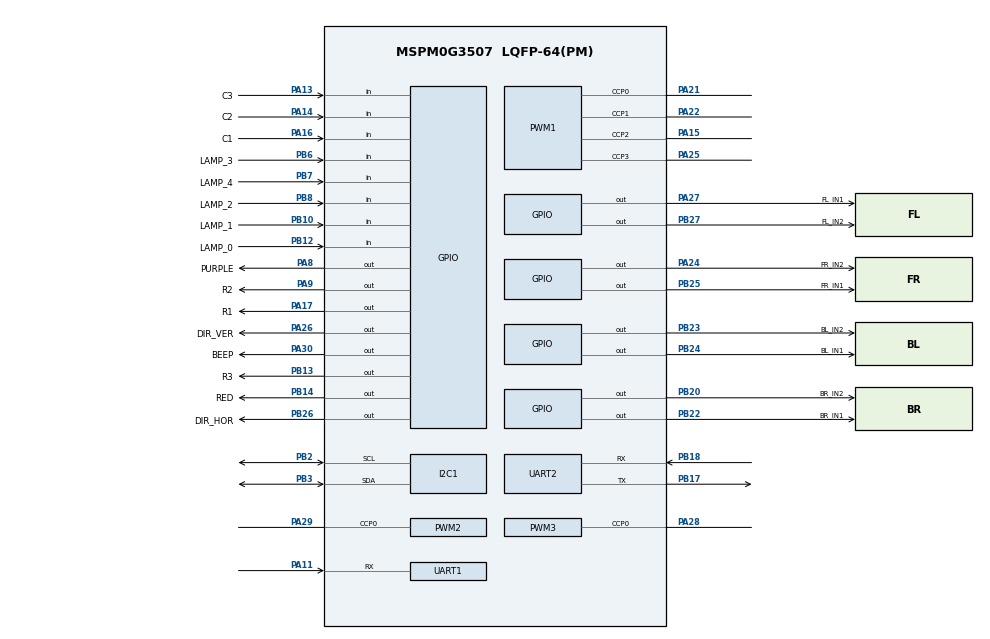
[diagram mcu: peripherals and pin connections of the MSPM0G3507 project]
/**
 * These arguments were used when this file was generated. They will be automatically applied on subsequent loads
 * via the GUI or CLI. Run CLI with '--help' for additional information on how to override these arguments.
 * @cliArgs --device "MSPM0G350X" --part "Default" --package "LQFP-64(PM)" --product "mspm0_sdk@2.05.00.05"
 * @v2CliArgs --device "MSPM0G3507" --package "LQFP-64(PM)" --product "mspm0_sdk@2.05.00.05"
 * @versions {"tool":"1.24.0+4110"}
 */

/**
 * Import the modules used in this configuration.
 */
const GPIO   = scripting.addModule("/ti/driverlib/GPIO", {}, false);
const GPIO1  = GPIO.addInstance();
const GPIO2  = GPIO.addInstance();
const GPIO3  = GPIO.addInstance();
const GPIO4  = GPIO.addInstance();
const GPIO5  = GPIO.addInstance();
const GPIO6  = GPIO.addInstance();
const GPIO7  = GPIO.addInstance();
const I2C    = scripting.addModule("/ti/driverlib/I2C", {}, false);
const I2C1   = I2C.addInstance();
const PWM    = scripting.addModule("/ti/driverlib/PWM", {}, false);
const PWM1   = PWM.addInstance();
const PWM2   = PWM.addInstance();
const PWM3   = PWM.addInstance();
const SYSCTL = scripting.addModule("/ti/driverlib/SYSCTL");
const TIMER  = scripting.addModule("/ti/driverlib/TIMER", {}, false);
const TIMER1 = TIMER.addInstance();
const UART   = scripting.addModule("/ti/driverlib/UART", {}, false);
const UART1  = UART.addInstance();
const UART2  = UART.addInstance();

/**
 * Write custom configuration values to the imported modules.
 */
const divider7       = system.clockTree["PLL_PDIV"];
divider7.divideValue = 2;

const divider9       = system.clockTree["UDIV"];
divider9.divideValue = 2;

const multiplier2         = system.clockTree["PLL_QDIV"];
multiplier2.multiplyValue = 5;

const mux8       = system.clockTree["HSCLKMUX"];
mux8.inputSelect = "HSCLKMUX_SYSPLL2X";

GPIO1.$name                              = "TRACE";
GPIO1.associatedPins.create(5);
GPIO1.associatedPins[0].direction        = "INPUT";
GPIO1.associatedPins[0].$name            = "LAMP_0";
GPIO1.associatedPins[0].internalResistor = "PULL_UP";
GPIO1.associatedPins[0].pin.$assign      = "PB12";
GPIO1.associatedPins[1].$name            = "LAMP_1";
GPIO1.associatedPins[1].direction        = "INPUT";
GPIO1.associatedPins[1].internalResistor = "PULL_UP";
GPIO1.associatedPins[1].pin.$assign      = "PB10";
GPIO1.associatedPins[2].$name            = "LAMP_2";
GPIO1.associatedPins[2].direction        = "INPUT";
GPIO1.associatedPins[2].internalResistor = "PULL_UP";
GPIO1.associatedPins[2].pin.$assign      = "PB8";
GPIO1.associatedPins[3].$name            = "LAMP_3";
GPIO1.associatedPins[3].direction        = "INPUT";
GPIO1.associatedPins[3].internalResistor = "PULL_UP";
GPIO1.associatedPins[3].pin.$assign      = "PB6";
GPIO1.associatedPins[4].$name            = "LAMP_4";
GPIO1.associatedPins[4].direction        = "INPUT";
GPIO1.associatedPins[4].internalResistor = "PULL_UP";
GPIO1.associatedPins[4].pin.$assign      = "PB7";

const Board = scripting.addModule("/ti/driverlib/Board", {}, false);

GPIO2.$name                         = "MOTOR";
GPIO2.associatedPins.create(8);
GPIO2.associatedPins[0].$name       = "FL_IN1";
GPIO2.associatedPins[0].pin.$assign = "PA27";
GPIO2.associatedPins[1].$name       = "FL_IN2";
GPIO2.associatedPins[1].pin.$assign = "PB27";
GPIO2.associatedPins[2].$name       = "FR_IN1";
GPIO2.associatedPins[2].pin.$assign = "PB25";
GPIO2.associatedPins[3].$name       = "FR_IN2";
GPIO2.associatedPins[3].pin.$assign = "PA24";
GPIO2.associatedPins[4].$name       = "BL_IN1";
GPIO2.associatedPins[4].pin.$assign = "PB24";
GPIO2.associatedPins[5].$name       = "BL_IN2";
GPIO2.associatedPins[5].pin.$assign = "PB23";
GPIO2.associatedPins[6].$name       = "BR_IN1";
GPIO2.associatedPins[6].pin.$assign = "PB22";
GPIO2.associatedPins[7].$name       = "BR_IN2";
GPIO2.associatedPins[7].pin.$assign = "PB20";

GPIO3.$name                         = "LED";
GPIO3.associatedPins[0].$name       = "RED";
GPIO3.associatedPins[0].pin.$assign = "PB14";

GPIO4.$name                         = "STEP";
GPIO4.associatedPins.create(2);
GPIO4.associatedPins[0].$name       = "DIR_VER";
GPIO4.associatedPins[0].pin.$assign = "PA26";
GPIO4.associatedPins[1].$name       = "DIR_HOR";
GPIO4.associatedPins[1].pin.$assign = "PB26";

GPIO5.$name                              = "KBD_GRP";
GPIO5.associatedPins.create(6);
GPIO5.associatedPins[0].$name            = "R1";
GPIO5.associatedPins[0].pin.$assign      = "PA17";
GPIO5.associatedPins[1].$name            = "R2";
GPIO5.associatedPins[1].pin.$assign      = "PA9";
GPIO5.associatedPins[2].$name            = "R3";
GPIO5.associatedPins[2].pin.$assign      = "PB13";
GPIO5.associatedPins[3].direction        = "INPUT";
GPIO5.associatedPins[3].internalResistor = "PULL_UP";
GPIO5.associatedPins[3].$name            = "C1";
GPIO5.associatedPins[3].pin.$assign      = "PA16";
GPIO5.associatedPins[4].$name            = "C2";
GPIO5.associatedPins[4].direction        = "INPUT";
GPIO5.associatedPins[4].internalResistor = "PULL_UP";
GPIO5.associatedPins[4].pin.$assign      = "PA14";
GPIO5.associatedPins[5].$name            = "C3";
GPIO5.associatedPins[5].direction        = "INPUT";
GPIO5.associatedPins[5].internalResistor = "PULL_UP";
GPIO5.associatedPins[5].pin.$assign      = "PA13";

GPIO6.$name                         = "LASER";
GPIO6.associatedPins[0].$name       = "PURPLE";
GPIO6.associatedPins[0].pin.$assign = "PA8";

GPIO7.$name                          = "BUZZER";
GPIO7.associatedPins[0].$name        = "BEEP";
GPIO7.associatedPins[0].initialValue = "SET";
GPIO7.associatedPins[0].pin.$assign  = "PA30";

I2C1.$name                             = "I2C_OLED";
I2C1.basicEnableController             = true;
I2C1.basicControllerStandardBusSpeed   = "Fast";
I2C1.peripheral.$assign                = "I2C1";
I2C1.peripheral.sdaPin.$assign         = "PB3";
I2C1.peripheral.sclPin.$assign         = "PB2";
I2C1.sdaPinConfig.hideOutputInversion  = scripting.forceWrite(false);
I2C1.sdaPinConfig.onlyInternalResistor = scripting.forceWrite(false);
I2C1.sdaPinConfig.passedPeripheralType = scripting.forceWrite("Digital");
I2C1.sdaPinConfig.$name                = "ti_driverlib_gpio_GPIOPinGeneric6";
I2C1.sclPinConfig.hideOutputInversion  = scripting.forceWrite(false);
I2C1.sclPinConfig.onlyInternalResistor = scripting.forceWrite(false);
I2C1.sclPinConfig.passedPeripheralType = scripting.forceWrite("Digital");
I2C1.sclPinConfig.$name                = "ti_driverlib_gpio_GPIOPinGeneric7";

PWM1.$name                              = "PWM_MOTOR";
PWM1.ccIndex                            = [0,1,2,3];
PWM1.clockPrescale                      = 2;
PWM1.pwmMode                            = "EDGE_ALIGN_UP";
PWM1.timerCount                         = 500;
PWM1.timerStartTimer                    = true;
PWM1.PWM_CHANNEL_0.$name                = "ti_driverlib_pwm_PWMTimerCC0";
PWM1.PWM_CHANNEL_1.$name                = "ti_driverlib_pwm_PWMTimerCC1";
PWM1.ccp0PinConfig.direction            = scripting.forceWrite("OUTPUT");
PWM1.ccp0PinConfig.hideOutputInversion  = scripting.forceWrite(false);
PWM1.ccp0PinConfig.onlyInternalResistor = scripting.forceWrite(false);
PWM1.ccp0PinConfig.passedPeripheralType = scripting.forceWrite("Digital");
PWM1.ccp0PinConfig.$name                = "ti_driverlib_gpio_GPIOPinGeneric0";
PWM1.ccp1PinConfig.direction            = scripting.forceWrite("OUTPUT");
PWM1.ccp1PinConfig.hideOutputInversion  = scripting.forceWrite(false);
PWM1.ccp1PinConfig.onlyInternalResistor = scripting.forceWrite(false);
PWM1.ccp1PinConfig.passedPeripheralType = scripting.forceWrite("Digital");
PWM1.ccp1PinConfig.$name                = "ti_driverlib_gpio_GPIOPinGeneric1";
PWM1.peripheral.$assign                 = "TIMA0";
PWM1.peripheral.ccp0Pin.$assign         = "PA21";
PWM1.peripheral.ccp1Pin.$assign         = "PA22";
PWM1.peripheral.ccp2Pin.$assign         = "PA15";
PWM1.peripheral.ccp3Pin.$assign         = "PA25";
PWM1.PWM_CHANNEL_2.$name                = "ti_driverlib_pwm_PWMTimerCC2";
PWM1.PWM_CHANNEL_3.$name                = "ti_driverlib_pwm_PWMTimerCC3";
PWM1.ccp2PinConfig.$name                = "ti_driverlib_gpio_GPIOPinGeneric8";
PWM1.ccp3PinConfig.$name                = "ti_driverlib_gpio_GPIOPinGeneric9";

PWM2.ccIndex                            = [0];
PWM2.clockPrescale                      = 8;
PWM2.interrupts                         = ["LOAD_EVENT"];
PWM2.interruptPriority                  = "1";
PWM2.timerCount                         = 5000;
PWM2.pwmMode                            = "EDGE_ALIGN_UP";
PWM2.$name                              = "SM_PUL_VER";
PWM2.PWM_CHANNEL_0.$name                = "ti_driverlib_pwm_PWMTimerCC4";
PWM2.ccp0PinConfig.direction            = scripting.forceWrite("OUTPUT");
PWM2.ccp0PinConfig.hideOutputInversion  = scripting.forceWrite(false);
PWM2.ccp0PinConfig.onlyInternalResistor = scripting.forceWrite(false);
PWM2.ccp0PinConfig.passedPeripheralType = scripting.forceWrite("Digital");
PWM2.ccp0PinConfig.$name                = "ti_driverlib_gpio_GPIOPinGeneric10";
PWM2.peripheral.ccp0Pin.$assign         = "PA29";

PWM3.ccIndex                            = [0];
PWM3.clockPrescale                      = 8;
PWM3.timerCount                         = 2000;
PWM3.interrupts                         = ["LOAD_EVENT"];
PWM3.interruptPriority                  = "1";
PWM3.pwmMode                            = "EDGE_ALIGN_UP";
PWM3.$name                              = "SM_PUL_HOR";
PWM3.PWM_CHANNEL_0.$name                = "ti_driverlib_pwm_PWMTimerCC5";
PWM3.ccp0PinConfig.direction            = scripting.forceWrite("OUTPUT");
PWM3.ccp0PinConfig.hideOutputInversion  = scripting.forceWrite(false);
PWM3.ccp0PinConfig.onlyInternalResistor = scripting.forceWrite(false);
PWM3.ccp0PinConfig.passedPeripheralType = scripting.forceWrite("Digital");
PWM3.ccp0PinConfig.$name                = "ti_driverlib_gpio_GPIOPinGeneric11";
PWM3.peripheral.ccp0Pin.$assign         = "PA28";

SYSCTL.forceDefaultClkConfig = true;
SYSCTL.clockTreeEn           = true;
scripting.suppress("For best practices when the CPUCLK is running at 32MHz and above, clear the flash status bit using DL_FlashCTL_executeClearStatus\\(\\) before executing any flash operation\\. Otherwise there may be false positives\\.", SYSCTL);

TIMER1.timerMode          = "PERIODIC";
TIMER1.timerPeriod        = "10 ms";
TIMER1.timerClkPrescale   = 256;
TIMER1.timerStartTimer    = true;
TIMER1.$name              = "MOTOR_TIM_INST";
TIMER1.peripheral.$assign = "TIMG0";

UART1.$name                            = "UART_WIT";
UART1.targetBaudRate                   = 115200;
UART1.direction                        = "RX";
UART1.enableFIFO                       = true;
UART1.rxTimeoutValue                   = 1;
UART1.enabledInterrupts                = ["RX_TIMEOUT_ERROR"];
UART1.enabledDMARXTriggers             = "DL_UART_DMA_INTERRUPT_RX";
UART1.interruptPriority                = "1";
UART1.rxPinConfig.hideOutputInversion  = scripting.forceWrite(false);
UART1.rxPinConfig.onlyInternalResistor = scripting.forceWrite(false);
UART1.rxPinConfig.passedPeripheralType = scripting.forceWrite("Digital");
UART1.rxPinConfig.$name                = "ti_driverlib_gpio_GPIOPinGeneric3";
UART1.peripheral.rxPin.$assign         = "PA11";
UART1.DMA_CHANNEL_RX.$name             = "DMA_WIT";
UART1.DMA_CHANNEL_RX.addressMode       = "f2b";
UART1.DMA_CHANNEL_RX.srcLength         = "BYTE";
UART1.DMA_CHANNEL_RX.dstLength         = "BYTE";

UART2.$name                            = "K230";
UART2.targetBaudRate                   = 115200;
UART2.enabledInterrupts                = ["RX"];
UART2.interruptPriority                = "1";
UART2.peripheral.rxPin.$assign         = "PB18";
UART2.peripheral.txPin.$assign         = "PB17";
UART2.txPinConfig.direction            = scripting.forceWrite("OUTPUT");
UART2.txPinConfig.hideOutputInversion  = scripting.forceWrite(false);
UART2.txPinConfig.onlyInternalResistor = scripting.forceWrite(false);
UART2.txPinConfig.passedPeripheralType = scripting.forceWrite("Digital");
UART2.txPinConfig.$name                = "ti_driverlib_gpio_GPIOPinGeneric4";
UART2.rxPinConfig.hideOutputInversion  = scripting.forceWrite(false);
UART2.rxPinConfig.onlyInternalResistor = scripting.forceWrite(false);
UART2.rxPinConfig.passedPeripheralType = scripting.forceWrite("Digital");
UART2.rxPinConfig.$name                = "ti_driverlib_gpio_GPIOPinGeneric5";

/**
 * Pinmux solution for unlocked pins/peripherals. This ensures that minor changes to the automatic solver in a future
 * version of the tool will not impact the pinmux you originally saw.  These lines can be completely deleted in order to
 * re-solve from scratch.
 */
Board.peripheral.$suggestSolution                = "DEBUGSS";
Board.peripheral.swclkPin.$suggestSolution       = "PA20";
Board.peripheral.swdioPin.$suggestSolution       = "PA19";
PWM2.peripheral.$suggestSolution                 = "TIMG6";
PWM3.peripheral.$suggestSolution                 = "TIMA1";
UART1.peripheral.$suggestSolution                = "UART0";
UART1.DMA_CHANNEL_RX.peripheral.$suggestSolution = "DMA_CH0";
UART2.peripheral.$suggestSolution                = "UART2";
